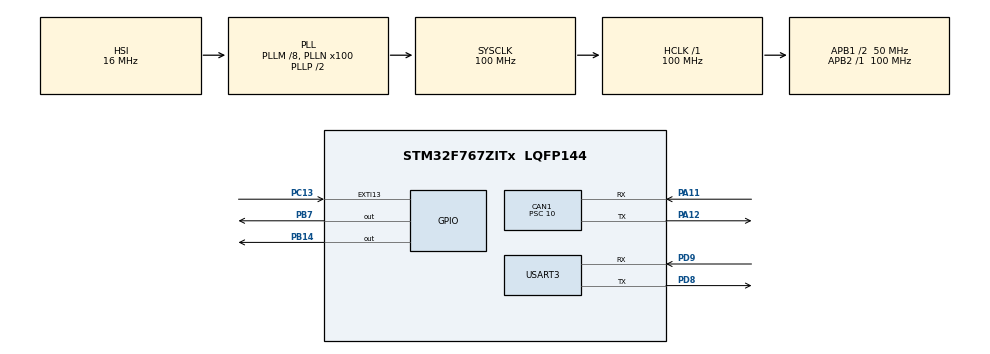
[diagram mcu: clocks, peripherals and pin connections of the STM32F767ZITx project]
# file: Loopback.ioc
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CAN1.BS1=CAN_BS1_8TQ
CAN1.CalculateBaudRate=500000
CAN1.CalculateTimeBit=2000
CAN1.CalculateTimeQuantum=200.0
CAN1.Mode=CAN_MODE_NORMAL
CAN1.NART=ENABLE
CAN1.Prescaler=10
CORTEX_M7.default_mode_Activation=1
Dma.Request0=USART3_RX
Dma.Request1=USART3_TX
Dma.USART3_RX.0.Direction=DMA_PERIPH_TO_MEMORY
Dma.USART3_RX.0.FIFOMode=DMA_FIFOMODE_DISABLE
Dma.USART3_RX.0.Instance=DMA1_Stream1
Dma.USART3_RX.0.MemDataAlignment=DMA_MDATAALIGN_BYTE
Dma.USART3_RX.0.MemInc=DMA_MINC_ENABLE
Dma.USART3_RX.0.Mode=DMA_NORMAL
Dma.USART3_RX.0.PeriphDataAlignment=DMA_PDATAALIGN_BYTE
Dma.USART3_RX.0.PeriphInc=DMA_PINC_DISABLE
Dma.USART3_RX.0.Priority=DMA_PRIORITY_HIGH
Dma.USART3_TX.1.Direction=DMA_MEMORY_TO_PERIPH
Dma.USART3_TX.1.FIFOMode=DMA_FIFOMODE_DISABLE
Dma.USART3_TX.1.Instance=DMA1_Stream3
Dma.USART3_TX.1.MemDataAlignment=DMA_MDATAALIGN_BYTE
Dma.USART3_TX.1.MemInc=DMA_MINC_ENABLE
Dma.USART3_TX.1.Mode=DMA_NORMAL
Dma.USART3_TX.1.PeriphDataAlignment=DMA_PDATAALIGN_BYTE
Dma.USART3_TX.1.PeriphInc=DMA_PINC_DISABLE
Dma.USART3_TX.1.Priority=DMA_PRIORITY_HIGH
FREERTOS.Tasks01=tasklampone,0,128,Startlampuone,Default,NULL,Dynamic,NULL,NULL;tasklamputwo,0,128,Startlamputwo,Default,NULL,Dynamic,NULL,NULL
FREERTOS.configUSE_NEWLIB_REENTRANT=1
Mcu.Family=STM32F7
Mcu.Name=STM32F767ZITx
Mcu.Package=LQFP144
NVIC.CAN1_RX0_IRQn=true\:5\:0\:false\:false\:true\:true\:true\:true\:true
NVIC.CAN1_RX1_IRQn=true\:5\:0\:false\:false\:true\:true\:true\:true\:true
NVIC.DMA1_Stream1_IRQn=true\:5\:0\:false\:false\:true\:true\:false\:true\:true
NVIC.DMA1_Stream3_IRQn=true\:5\:0\:false\:false\:true\:true\:false\:true\:true
NVIC.EXTI15_10_IRQn=true\:5\:0\:false\:false\:true\:true\:true\:true\:true
NVIC.PriorityGroup=NVIC_PRIORITYGROUP_4
NVIC.TIM1_UP_TIM10_IRQn=true\:15\:0\:false\:false\:true\:false\:false\:true\:true
NVIC.TimeBase=TIM1_UP_TIM10_IRQn
NVIC.TimeBaseIP=TIM1
NVIC.USART3_IRQn=true\:5\:0\:false\:false\:true\:true\:true\:true\:true
PA11.Mode=CAN_Activate
PA11.Signal=CAN1_RX
PA12.Mode=CAN_Activate
PA12.Signal=CAN1_TX
PB14.Signal=GPIO_Output
PB7.Signal=GPIO_Output
PC13.Signal=GPXTI13
PD8.Mode=Asynchronous
PD8.Signal=USART3_TX
PD9.Mode=Asynchronous
PD9.Signal=USART3_RX
PH0/OSC_IN.Mode=HSE-External-Oscillator
PH0/OSC_IN.Signal=RCC_OSC_IN
PH1/OSC_OUT.Mode=HSE-External-Oscillator
PH1/OSC_OUT.Signal=RCC_OSC_OUT
ProjectManager.HeapSize=0x200
ProjectManager.StackSize=0x400
ProjectManager.TargetToolchain=STM32CubeIDE
RCC.AHBFreq_Value=100000000
RCC.APB1CLKDivider=RCC_HCLK_DIV2
RCC.APB1Freq_Value=50000000
RCC.APB1TimFreq_Value=100000000
RCC.APB2Freq_Value=100000000
RCC.APB2TimFreq_Value=100000000
RCC.CortexFreq_Value=100000000
RCC.HCLKFreq_Value=100000000
RCC.HSE_VALUE=25000000
RCC.HSI_VALUE=16000000
RCC.LSE_VALUE=32768
RCC.PLLM=12
RCC.PLLN=96
RCC.PLLSourceVirtual=RCC_PLLSOURCE_HSE
RCC.SYSCLKFreq_VALUE=100000000
RCC.SYSCLKSource=RCC_SYSCLKSOURCE_PLLCLK
RCC.USBFreq_Value=100000000
RCC.VCOOutputFreq_Value=200000000
USART3.VirtualMode-Asynchronous=VM_ASYNC
VP_FREERTOS_VS_CMSIS_V1.Mode=CMSIS_V1
VP_SYS_VS_tim1.Mode=TIM1
board=custom

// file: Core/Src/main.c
/* USER CODE BEGIN Header */
/**
  ******************************************************************************
  * @file           : main.c
  * @brief          : Main program body
  ******************************************************************************
  * @attention
  *
  * Copyright (c) 2024 STMicroelectronics.
  * All rights reserved.
  *
  * This software is licensed under terms that can be found in the LICENSE file
  * in the root directory of this software component.
  * If no LICENSE file comes with this software, it is provided AS-IS.
  *
  ******************************************************************************
  */
/* USER CODE END Header */
#include "main.h"
#include "cmsis_os.h"

CAN_HandleTypeDef hcan1;

UART_HandleTypeDef huart3;
DMA_HandleTypeDef hdma_usart3_rx;
DMA_HandleTypeDef hdma_usart3_tx;

osThreadId tasklamponeHandle;
osThreadId tasklamputwoHandle;
/* USER CODE BEGIN PV */
osThreadId tasklamputhreeHandle;
osThreadId taskstartallHandle;
osThreadId taskstopallHandle;

CAN_TxHeaderTypeDef   TxHeader;
CAN_RxHeaderTypeDef   RxHeader;
uint8_t               TxData[8];
uint8_t               RxData[8];
uint32_t              TxMailbox;

volatile uint8_t taskControl = 0;

uint8_t uart_bfr, cmd;
uint16_t buffer, counter=0;
char rxbuffer[1];
uint8_t led_status;
uint8_t cmdstate=0;
uint32_t blinktimer;
uint8_t blinkstatus;
uint8_t pembawa;
uint8_t uart_buffer[128];
static uint8_t UART_SendFlag=1;
uint8_t menu_cmd[]={"\
  \r\nLED ON           ----> 1 \
  \r\nLED OFF          ----> 2 \
  \r\nLED TOGGLE (2S)  ----> 3 \
  \r\nLED TOGGLE OFF   ----> 6 \
  \r\nLED READ STATUS  ----> 7 \
  \r\nType your option here : \n"};
/* USER CODE END PV */

void SystemClock_Config(void);
static void MPU_Config(void);
static void MX_GPIO_Init(void);
static void MX_DMA_Init(void);
static void MX_CAN1_Init(void);
static void MX_USART3_UART_Init(void);
void Startlampuone(void const * argument);
void Startlamputwo(void const * argument);
void Startlamputhree(void const * argument);
void StartAll(void const * argument);
void StopAll(void const * argument);

/* USER CODE BEGIN 0 */
// PA 12 TX
void HAL_UART_RxCpltCallback(UART_HandleTypeDef *huart){
	if (huart -> Instance == USART3)
	{switch (rxbuffer[0]) {
	case '1':
		TxData[0] = 0x03;
		TxData[1] = 0xAD;
		if (HAL_CAN_AddTxMessage(&hcan1, &TxHeader, TxData, &TxMailbox) != HAL_OK)
			{
						/* Transmission request Error */
						Error_Handler();
			}
		taskControl = 1; // Enable Task 1
		break;
	case '2':
			TxData[0] = 0x06;
			TxData[1] = 0xBD;
			if (HAL_CAN_AddTxMessage(&hcan1, &TxHeader, TxData, &TxMailbox) != HAL_OK)
				{
							/* Transmission request Error */
							Error_Handler();
				}
			taskControl = 2; // Enable Task 2
			break;
	case '3':
			TxData[0] = 0x07;
			TxData[1] = 0xCE;
			if (HAL_CAN_AddTxMessage(&hcan1, &TxHeader, TxData, &TxMailbox) != HAL_OK)
				{
							/* Transmission request Error */
							Error_Handler();
				}
			taskControl = 3; // Enable Task 3
			break;
	case '4':
				TxData[0] = 0x08;
				TxData[1] = 0xDE;
				if (HAL_CAN_AddTxMessage(&hcan1, &TxHeader, TxData, &TxMailbox) != HAL_OK)
					{
								/* Transmission request Error */
								Error_Handler();
					}
				taskControl = 4; // Enable Task 3
				break;
	case '5':
		TxData[0] = 0x09;
						TxData[1] = 0xBE;
						if (HAL_CAN_AddTxMessage(&hcan1, &TxHeader, TxData, &TxMailbox) != HAL_OK)
							{
										/* Transmission request Error */
										Error_Handler();
							}
	         taskControl = 5; // Stop both tasks
	         break;
	     default:
	         break;
	}
	HAL_UART_Receive_IT(&huart3, (uint8_t *)rxbuffer, sizeof(rxbuffer));
	}

}

/* USER CODE END 0 */

int main(void)
{

  /* MPU Configuration--------------------------------------------------------*/
  MPU_Config();

  /* MCU Configuration--------------------------------------------------------*/

  /* Reset of all peripherals, Initializes the Flash interface and the Systick. */
  HAL_Init();

  /* Configure the system clock */
  SystemClock_Config();

  /* Initialize all configured peripherals */
  MX_GPIO_Init();
  MX_DMA_Init();
  MX_CAN1_Init();
  MX_USART3_UART_Init();
  /* USER CODE BEGIN 2 */
  HAL_UART_Receive_DMA(&huart3, rxbuffer, 1);

  /* USER CODE END 2 */

  /* Create the thread(s) */
  /* definition and creation of tasklampone */
  osThreadDef(tasklampone, Startlampuone, osPriorityNormal, 0, 128);
  tasklamponeHandle = osThreadCreate(osThread(tasklampone), NULL);

  /* definition and creation of tasklamputwo */
  osThreadDef(tasklamputwo, Startlamputwo, osPriorityNormal, 0, 128);
  tasklamputwoHandle = osThreadCreate(osThread(tasklamputwo), NULL);

  /* USER CODE BEGIN RTOS_THREADS */
  /* definition and creation of tasklamputhree */
    osThreadDef(tasklamputhree, Startlamputhree, osPriorityNormal, 0, 128);
    tasklamputhreeHandle = osThreadCreate(osThread(tasklamputhree), NULL);

    osThreadDef(startall, StartAll, osPriorityNormal, 0, 128);
    taskstartallHandle = osThreadCreate(osThread(startall), NULL);

    osThreadDef(stopall, StopAll, osPriorityNormal, 0, 128);
    taskstopallHandle = osThreadCreate(osThread(stopall), NULL);
  /* add threads, ... */
  /* USER CODE END RTOS_THREADS */
    //void StartAll(void const * argument);
  /* Start scheduler */
  osKernelStart();

  /* We should never get here as control is now taken by the scheduler */

  /* Infinite loop */
  while (1)
  {

  }
}

void SystemClock_Config(void)
{
  RCC_OscInitTypeDef RCC_OscInitStruct = {0};
  RCC_ClkInitTypeDef RCC_ClkInitStruct = {0};

  /** Configure the main internal regulator output voltage
  */
  __HAL_RCC_PWR_CLK_ENABLE();
  __HAL_PWR_VOLTAGESCALING_CONFIG(PWR_REGULATOR_VOLTAGE_SCALE3);

  /** Initializes the RCC Oscillators according to the specified parameters
  * in the RCC_OscInitTypeDef structure.
  */
  RCC_OscInitStruct.OscillatorType = RCC_OSCILLATORTYPE_HSI;
  RCC_OscInitStruct.HSIState = RCC_HSI_ON;
  RCC_OscInitStruct.HSICalibrationValue = RCC_HSICALIBRATION_DEFAULT;
  RCC_OscInitStruct.PLL.PLLState = RCC_PLL_ON;
  RCC_OscInitStruct.PLL.PLLSource = RCC_PLLSOURCE_HSI;
  RCC_OscInitStruct.PLL.PLLM = 8;
  RCC_OscInitStruct.PLL.PLLN = 100;
  RCC_OscInitStruct.PLL.PLLP = RCC_PLLP_DIV2;
  RCC_OscInitStruct.PLL.PLLQ = 2;
  RCC_OscInitStruct.PLL.PLLR = 2;
  if (HAL_RCC_OscConfig(&RCC_OscInitStruct) != HAL_OK)
  {
    Error_Handler();
  }

  /** Activate the Over-Drive mode
  */
  if (HAL_PWREx_EnableOverDrive() != HAL_OK)
  {
    Error_Handler();
  }

  /** Initializes the CPU, AHB and APB buses clocks
  */
  RCC_ClkInitStruct.ClockType = RCC_CLOCKTYPE_HCLK|RCC_CLOCKTYPE_SYSCLK
                              |RCC_CLOCKTYPE_PCLK1|RCC_CLOCKTYPE_PCLK2;
  RCC_ClkInitStruct.SYSCLKSource = RCC_SYSCLKSOURCE_PLLCLK;
  RCC_ClkInitStruct.AHBCLKDivider = RCC_SYSCLK_DIV1;
  RCC_ClkInitStruct.APB1CLKDivider = RCC_HCLK_DIV2;
  RCC_ClkInitStruct.APB2CLKDivider = RCC_HCLK_DIV1;

  if (HAL_RCC_ClockConfig(&RCC_ClkInitStruct, FLASH_LATENCY_3) != HAL_OK)
  {
    Error_Handler();
  }
}

static void MX_CAN1_Init(void)
{

  hcan1.Instance = CAN1;
  hcan1.Init.Prescaler = 5;
  hcan1.Init.Mode = CAN_MODE_NORMAL;
  hcan1.Init.SyncJumpWidth = CAN_SJW_1TQ;
  hcan1.Init.TimeSeg1 = CAN_BS1_8TQ;
  hcan1.Init.TimeSeg2 = CAN_BS2_1TQ;
  hcan1.Init.TimeTriggeredMode = DISABLE;
  hcan1.Init.AutoBusOff = DISABLE;
  hcan1.Init.AutoWakeUp = DISABLE;
  hcan1.Init.AutoRetransmission = ENABLE;
  hcan1.Init.ReceiveFifoLocked = DISABLE;
  hcan1.Init.TransmitFifoPriority = DISABLE;
  if (HAL_CAN_Init(&hcan1) != HAL_OK)
  {
    Error_Handler();
  }
  /* USER CODE BEGIN CAN1_Init 2 */

  	CAN_FilterTypeDef  sFilterConfig;

  	sFilterConfig.FilterBank = 0;
    sFilterConfig.FilterMode = CAN_FILTERMODE_IDMASK;
    sFilterConfig.FilterScale = CAN_FILTERSCALE_32BIT;
    sFilterConfig.FilterIdHigh = 0x103<<5;
    sFilterConfig.FilterIdLow = 0x0000;
    sFilterConfig.FilterMaskIdHigh = 0x103<<5;
    sFilterConfig.FilterMaskIdLow = 0x0000;
    sFilterConfig.FilterFIFOAssignment = CAN_RX_FIFO0;
    sFilterConfig.FilterActivation = ENABLE;
    sFilterConfig.SlaveStartFilterBank = 14;

    if(HAL_CAN_ConfigFilter(&hcan1, &sFilterConfig) != HAL_OK)
      {
        /* Filter configuration Error */
        Error_Handler();
      }

      /*##-3- Start the CAN peripheral ###########################################*/

    if (HAL_CAN_Start(&hcan1) != HAL_OK)
      {
        /* Start Error */
        Error_Handler();
      }

    if (HAL_CAN_ActivateNotification(&hcan1, CAN_IT_RX_FIFO0_MSG_PENDING) != HAL_OK)
        {
          /* Notification Error */
          Error_Handler();
        }

      	TxHeader.StdId = 0x103;
        TxHeader.RTR = CAN_RTR_DATA;
        TxHeader.IDE = CAN_ID_STD;
        TxHeader.DLC = 2;
        TxHeader.TransmitGlobalTime = DISABLE;
        HAL_Delay(1);

  /* USER CODE END CAN1_Init 2 */

}

static void MX_USART3_UART_Init(void)
{

  huart3.Instance = USART3;
  huart3.Init.BaudRate = 115200;
  huart3.Init.WordLength = UART_WORDLENGTH_8B;
  huart3.Init.StopBits = UART_STOPBITS_1;
  huart3.Init.Parity = UART_PARITY_NONE;
  huart3.Init.Mode = UART_MODE_TX_RX;
  huart3.Init.HwFlowCtl = UART_HWCONTROL_NONE;
  huart3.Init.OverSampling = UART_OVERSAMPLING_16;
  huart3.Init.OneBitSampling = UART_ONE_BIT_SAMPLE_DISABLE;
  huart3.AdvancedInit.AdvFeatureInit = UART_ADVFEATURE_NO_INIT;
  if (HAL_UART_Init(&huart3) != HAL_OK)
  {
    Error_Handler();
  }

}

static void MX_DMA_Init(void)
{

  /* DMA controller clock enable */
  __HAL_RCC_DMA1_CLK_ENABLE();

  /* DMA interrupt init */
  /* DMA1_Stream1_IRQn interrupt configuration */
  HAL_NVIC_SetPriority(DMA1_Stream1_IRQn, 5, 0);
  HAL_NVIC_EnableIRQ(DMA1_Stream1_IRQn);
  /* DMA1_Stream3_IRQn interrupt configuration */
  HAL_NVIC_SetPriority(DMA1_Stream3_IRQn, 5, 0);
  HAL_NVIC_EnableIRQ(DMA1_Stream3_IRQn);

}

static void MX_GPIO_Init(void)
{
  GPIO_InitTypeDef GPIO_InitStruct = {0};

  /* GPIO Ports Clock Enable */
  __HAL_RCC_GPIOC_CLK_ENABLE();
  __HAL_RCC_GPIOH_CLK_ENABLE();
  __HAL_RCC_GPIOB_CLK_ENABLE();
  __HAL_RCC_GPIOD_CLK_ENABLE();
  __HAL_RCC_GPIOA_CLK_ENABLE();

  /*Configure GPIO pin Output Level */
  HAL_GPIO_WritePin(GPIOB, GPIO_PIN_14|GPIO_PIN_7, GPIO_PIN_RESET);

  /*Configure GPIO pin : PC13 */
  GPIO_InitStruct.Pin = GPIO_PIN_13;
  GPIO_InitStruct.Mode = GPIO_MODE_IT_RISING;
  GPIO_InitStruct.Pull = GPIO_NOPULL;
  HAL_GPIO_Init(GPIOC, &GPIO_InitStruct);

  /*Configure GPIO pins : PB14 PB7 */
  GPIO_InitStruct.Pin = GPIO_PIN_14|GPIO_PIN_7|GPIO_PIN_0;
  GPIO_InitStruct.Mode = GPIO_MODE_OUTPUT_PP;
  GPIO_InitStruct.Pull = GPIO_NOPULL;
  GPIO_InitStruct.Speed = GPIO_SPEED_FREQ_LOW;
  HAL_GPIO_Init(GPIOB, &GPIO_InitStruct);

  /* EXTI interrupt init*/
  HAL_NVIC_SetPriority(EXTI15_10_IRQn, 5, 0);
  HAL_NVIC_EnableIRQ(EXTI15_10_IRQn);

}

/* USER CODE BEGIN 4 */
void send_uart_dma(uint8_t* ptr, uint16_t len){
	while(!UART_SendFlag);

	UART_SendFlag=0;
	HAL_UART_Transmit_DMA(&huart3, (uint8_t*)ptr, len);

}

void HAL_UART_TxCpltCallback(UART_HandleTypeDef *huart){
	UART_SendFlag=1;
}

void HAL_CAN_RxFifo0MsgPendingCallback(CAN_HandleTypeDef *hcan)
{
  /* Get RX message */
  if (HAL_CAN_GetRxMessage(hcan, CAN_RX_FIFO0, &RxHeader, RxData) != HAL_OK)
  {
    /* Reception Error */
    Error_Handler();
  }

  /* Display LEDx */
  if ((RxHeader.StdId == 0x103) && (RxHeader.IDE == CAN_ID_STD) && (RxHeader.DLC == 2))
  {
	  HAL_GPIO_TogglePin(GPIOB, GPIO_PIN_13);
  }
}

/* USER CODE END 4 */

void Startlampuone(void const * argument)
{
  /* USER CODE BEGIN 5 */
  /* Infinite loop */
	while (1) {
		        if (taskControl == 1) {
		            HAL_GPIO_WritePin(GPIOB, GPIO_PIN_7, GPIO_PIN_RESET);
		            HAL_GPIO_WritePin(GPIOB, GPIO_PIN_14, GPIO_PIN_RESET);
		            HAL_GPIO_TogglePin(GPIOB, GPIO_PIN_0); // Toggle PB7
		            osDelay(1000); // Delay for 500 ms

		        } else {
		            osDelay(100); // Prevent busy waiting
		        }
		    }
  /* USER CODE END 5 */
}

void Startlamputwo(void const * argument)
{
  /* USER CODE BEGIN Startlamputwo */
  /* Infinite loop */
	while (1) {
		        if (taskControl == 2) {
		            HAL_GPIO_WritePin(GPIOB, GPIO_PIN_0, GPIO_PIN_RESET);
		            HAL_GPIO_WritePin(GPIOB, GPIO_PIN_14, GPIO_PIN_RESET);
		            HAL_GPIO_TogglePin(GPIOB, GPIO_PIN_7); // Toggle PB14
		            osDelay(1000); // Delay for 500 ms

		        } else {
		            osDelay(100); // Prevent busy waiting
		        }
		    }
  /* USER CODE END Startlamputwo */
}

void StartAll(void const * argument)
{
  /* USER CODE BEGIN Startlamputhree */
  /* Infinite loop */
	while (1) {
		        if (taskControl == 4) {
		        	HAL_GPIO_TogglePin(GPIOB, GPIO_PIN_0); // Toggle PB14
		            HAL_GPIO_TogglePin(GPIOB, GPIO_PIN_7); // Toggle PB14
		            HAL_GPIO_TogglePin(GPIOB, GPIO_PIN_14); // Toggle PB14
		            osDelay(1000); // Delay for 500 ms

		        } else {
		            osDelay(100); // Prevent busy waiting
		        }
		    }
  /* USER CODE END Startlamputwo */
}

void Startlamputhree(void const * argument)
{
  /* USER CODE BEGIN Startlamputhree */
  /* Infinite loop */
	while (1) {
		        if (taskControl == 3) {
		            HAL_GPIO_WritePin(GPIOB, GPIO_PIN_0, GPIO_PIN_RESET);
		            HAL_GPIO_WritePin(GPIOB, GPIO_PIN_7, GPIO_PIN_RESET);
		            HAL_GPIO_TogglePin(GPIOB, GPIO_PIN_14); // Toggle PB14
		            osDelay(1000); // Delay for 500 ms

		        } else {
		            osDelay(100); // Prevent busy waiting
		        }
		    }
  /* USER CODE END Startlamputwo */
}

void StopAll(void const * argument){
	while (1) {
			        if (taskControl == 5) {
			            HAL_GPIO_WritePin(GPIOB, GPIO_PIN_0, GPIO_PIN_RESET);
			            HAL_GPIO_WritePin(GPIOB, GPIO_PIN_7, GPIO_PIN_RESET);
			            HAL_GPIO_WritePin(GPIOB, GPIO_PIN_14, GPIO_PIN_RESET);// Toggle PB14
			            osDelay(1000); // Delay for 500 ms

			        } else {
			            osDelay(100); // Prevent busy waiting
			        }
			    }
}
 /* MPU Configuration */

void MPU_Config(void)
{
  MPU_Region_InitTypeDef MPU_InitStruct = {0};

  /* Disables the MPU */
  HAL_MPU_Disable();

  /** Initializes and configures the Region and the memory to be protected
  */
  MPU_InitStruct.Enable = MPU_REGION_ENABLE;
  MPU_InitStruct.Number = MPU_REGION_NUMBER0;
  MPU_InitStruct.BaseAddress = 0x0;
  MPU_InitStruct.Size = MPU_REGION_SIZE_4GB;
  MPU_InitStruct.SubRegionDisable = 0x87;
  MPU_InitStruct.TypeExtField = MPU_TEX_LEVEL0;
  MPU_InitStruct.AccessPermission = MPU_REGION_NO_ACCESS;
  MPU_InitStruct.DisableExec = MPU_INSTRUCTION_ACCESS_DISABLE;
  MPU_InitStruct.IsShareable = MPU_ACCESS_SHAREABLE;
  MPU_InitStruct.IsCacheable = MPU_ACCESS_NOT_CACHEABLE;
  MPU_InitStruct.IsBufferable = MPU_ACCESS_NOT_BUFFERABLE;

  HAL_MPU_ConfigRegion(&MPU_InitStruct);
  /* Enables the MPU */
  HAL_MPU_Enable(MPU_PRIVILEGED_DEFAULT);

}

void HAL_TIM_PeriodElapsedCallback(TIM_HandleTypeDef *htim)
{
  if (htim->Instance == TIM1) {
    HAL_IncTick();
  }
}

void Error_Handler(void)
{
  __disable_irq();
  while (1)
  {
  }
}
